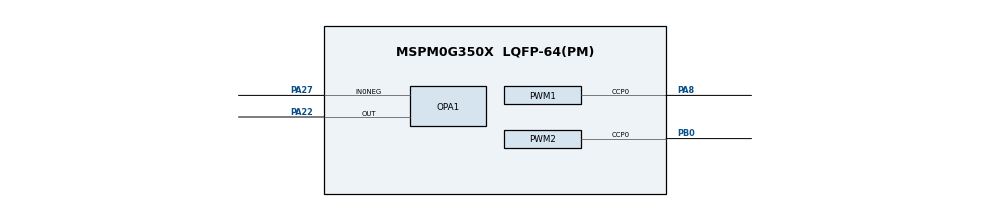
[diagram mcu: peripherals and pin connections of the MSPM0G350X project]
/**
 * @cliArgs --device "MSPM0G350X" --part "Default" --package "LQFP-64(PM)" --product "mspm0_sdk@2.10.00.04"
 * @versions {"tool":"1.26.2+4477"}
 */

/**
 * Import the modules used in this configuration.
 */
const ADC12  = scripting.addModule("/ti/driverlib/ADC12", {}, false);
const ADC121 = ADC12.addInstance();
const OPA    = scripting.addModule("/ti/driverlib/OPA", {}, false);
const OPA1   = OPA.addInstance();
const PWM    = scripting.addModule("/ti/driverlib/PWM", {}, false);
const PWM1   = PWM.addInstance();
const PWM2   = PWM.addInstance();
const SYSCTL = scripting.addModule("/ti/driverlib/SYSCTL");
const TIMER  = scripting.addModule("/ti/driverlib/TIMER", {}, false);
const TIMER1 = TIMER.addInstance();
const VREF   = scripting.addModule("/ti/driverlib/VREF");

/**
 * Write custom configuration values to the imported modules.
 */
ADC121.$name                 = "ADC12_0";
ADC121.samplingOperationMode = "sequence";
ADC121.endAdd                = 1;
ADC121.adcMem0chansel        = "DL_ADC12_INPUT_CHAN_5";
ADC121.adcMem1chansel        = "DL_ADC12_INPUT_CHAN_13";
ADC121.adcMem1stime          = "DL_ADC12_SAMPLE_TIMER_SOURCE_SCOMP1";
ADC121.adcMem1avgen          = true;
ADC121.sampleTime0           = "1 ms";
ADC121.sampleTime1           = "4 ms";
ADC121.enabledInterrupts     = ["DL_ADC12_INTERRUPT_MEM0_RESULT_LOADED","DL_ADC12_INTERRUPT_MEM1_RESULT_LOADED"];
ADC121.sampClkDiv            = "DL_ADC12_CLOCK_DIVIDE_48";
ADC121.adcPin5Config.$name   = "ti_driverlib_gpio_GPIOPinGeneric4";
ADC121.peripheral.$assign    = "ADC0";

const Board = scripting.addModule("/ti/driverlib/Board", {}, false);

OPA1.$name                        = "OPA_0";
OPA1.cfg0PSELChannel              = "VREF";
OPA1.cfg0NSELChannel              = "IN0_NEG";
OPA1.cfg0Gain                     = "N1_P2";
OPA1.cfg0OutputPin                = "ENABLED";
OPA1.In0NegPinConfig.$name        = "ti_driverlib_gpio_GPIOPinGeneric1";
OPA1.peripheral.$assign           = "OPA0";
OPA1.peripheral.In0NegPin.$assign = "PA27";
OPA1.peripheral.OutPin.$assign    = "PA22";
OPA1.OutPinConfig.$name           = "ti_driverlib_gpio_GPIOPinGeneric2";

PWM1.$name                      = "PWM_0";
PWM1.timerCount                 = 5000;
PWM1.ccIndex                    = [0];
PWM1.interrupts                 = ["ZERO_EVENT"];
PWM1.interruptPriority          = "0";
PWM1.clockSource                = "MFCLK";
PWM1.clockDivider               = 2;
PWM1.PWM_CHANNEL_0.$name        = "ti_driverlib_pwm_PWMTimerCC0";
PWM1.PWM_CHANNEL_0.dutyCycle    = 50;
PWM1.ccp0PinConfig.$name        = "ti_driverlib_gpio_GPIOPinGeneric3";
PWM1.ccp0PinConfig.enableConfig = true;
PWM1.peripheral.ccp0Pin.$assign = "PA8";

PWM2.$name                      = "PWM_1";
PWM2.clockSource                = "MFCLK";
PWM2.interrupts                 = ["ZERO_EVENT"];
PWM2.interruptPriority          = "0";
PWM2.timerCount                 = 5000;
PWM2.clockDivider               = 2;
PWM2.ccIndex                    = [0];
PWM2.PWM_CHANNEL_0.$name        = "ti_driverlib_pwm_PWMTimerCC1";
PWM2.PWM_CHANNEL_0.dutyCycle    = 50;
PWM2.ccp0PinConfig.$name        = "ti_driverlib_gpio_GPIOPinGeneric5";
PWM2.peripheral.ccp0Pin.$assign = "PB0";

SYSCTL.forceDefaultClkConfig = true;
SYSCTL.LFCLKSource           = "LFXT";
SYSCTL.HFCLK_Freq            = 40000000;
SYSCTL.SYSPLLSource          = "HFCLK";
SYSCTL.SYSPLL_Pdiv           = 4;
SYSCTL.SYSPLL_Qdiv           = 8;
SYSCTL.SYSPLL_CLK2XDiv       = 1;
SYSCTL.HSCLKSource           = "SYSPLLCLK2X";
SYSCTL.MFCLKEn               = true;

TIMER1.$name            = "TIMER_0";
TIMER1.interrupts       = ["ZERO"];
TIMER1.timerPeriod      = "33.33 ms";
TIMER1.timerClkDiv      = 8;
TIMER1.timerClkPrescale = 255;
TIMER1.timerMode        = "PERIODIC_UP";

VREF.checkVREFReady         = true;
VREF.vrefPosPinConfig.$name = "ti_driverlib_gpio_GPIOPinGeneric0";

/**
 * Pinmux solution for unlocked pins/peripherals. This ensures that minor changes to the automatic solver in a future
 * version of the tool will not impact the pinmux you originally saw.  These lines can be completely deleted in order to
 * re-solve from scratch.
 */
ADC121.peripheral.adcPin5.$suggestSolution   = "PB24";
Board.peripheral.$suggestSolution            = "DEBUGSS";
Board.peripheral.swclkPin.$suggestSolution   = "PA20";
Board.peripheral.swdioPin.$suggestSolution   = "PA19";
PWM1.peripheral.$suggestSolution             = "TIMA0";
PWM2.peripheral.$suggestSolution             = "TIMA1";
SYSCTL.peripheral.$suggestSolution           = "SYSCTL";
SYSCTL.peripheral.lfxInPin.$suggestSolution  = "PA3";
SYSCTL.peripheral.lfxOutPin.$suggestSolution = "PA4";
TIMER1.peripheral.$suggestSolution           = "TIMG0";
VREF.peripheral.$suggestSolution             = "VREF";
VREF.peripheral.vrefPosPin.$suggestSolution  = "PA23";
